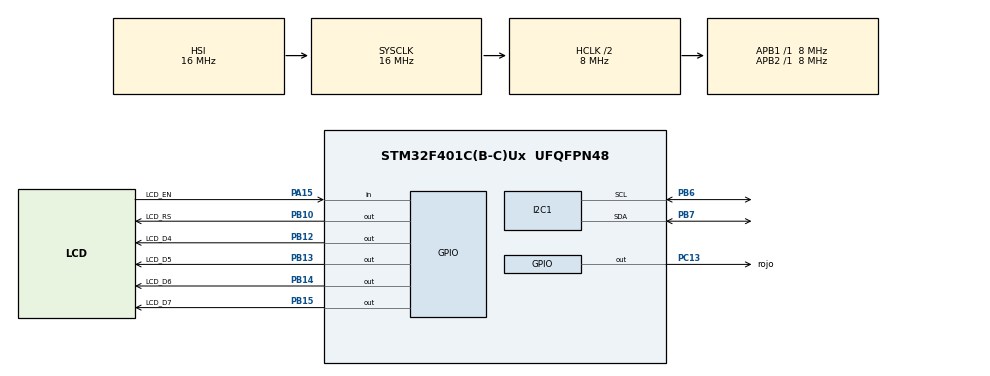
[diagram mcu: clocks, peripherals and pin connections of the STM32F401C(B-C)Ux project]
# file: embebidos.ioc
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Mcu.Family=STM32F4
Mcu.Name=STM32F401C(B-C)Ux
Mcu.Package=UFQFPN48
Mcu.UserConstants=i2c_pin,$$_I2C1_IP_HANDLE_$$
NVIC.PriorityGroup=NVIC_PRIORITYGROUP_4
PA15.GPIO_Label=LCD_EN
PA15.Signal=GPIO_Input
PB10.GPIO_Label=LCD_RS
PB10.Signal=GPIO_Output
PB12.GPIO_Label=LCD_D4
PB12.Signal=GPIO_Output
PB13.GPIO_Label=LCD_D5
PB13.Signal=GPIO_Output
PB14.GPIO_Label=LCD_D6
PB14.Signal=GPIO_Output
PB15.GPIO_Label=LCD_D7
PB15.Signal=GPIO_Output
PB6.Mode=I2C
PB6.Signal=I2C1_SCL
PB7.Mode=I2C
PB7.Signal=I2C1_SDA
PC13-ANTI_TAMP.GPIO_Label=rojo
PC13-ANTI_TAMP.Signal=GPIO_Output
ProjectManager.HeapSize=0x200
ProjectManager.StackSize=0x400
ProjectManager.TargetToolchain=CMake
RCC.AHBCLKDivider=RCC_SYSCLK_DIV2
RCC.AHBFreq_Value=8000000
RCC.APB1Freq_Value=8000000
RCC.APB1TimFreq_Value=8000000
RCC.APB2Freq_Value=8000000
RCC.APB2TimFreq_Value=8000000
RCC.CortexFreq_Value=8000000
RCC.HCLKFreq_Value=8000000
RCC.HSE_VALUE=25000000
RCC.HSI_VALUE=16000000
RCC.LSE_VALUE=32768
RCC.SYSCLKFreq_VALUE=16000000
RCC.VCOOutputFreq_Value=192000000
board=custom

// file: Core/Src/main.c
/* USER CODE BEGIN Header */
/**
  ******************************************************************************
  * @file           : main.c
  * @brief          : Main program body
  ******************************************************************************
  * @attention
  *
  * Copyright (c) 2026 STMicroelectronics.
  * All rights reserved.
  *
  * This software is licensed under terms that can be found in the LICENSE file
  * in the root directory of this software component.
  * If no LICENSE file comes with this software, it is provided AS-IS.
  *
  ******************************************************************************
  */
/* USER CODE END Header */
#include "main.h"

/* USER CODE BEGIN Includes */
#include "LCD_I2C.H"
#include "lcd.h"

const char rayo[8] = {0x02, 0x04, 0x08, 0x1F, 0x04, 0x08, 0x10, 0x00};
const char carita[8] = {0x00, 0x0A, 0x0A, 0x00, 0x11, 0x0E, 0x00, 0x00};

/* USER CODE END Includes */

I2C_HandleTypeDef hi2c1;

void SystemClock_Config(void);
static void MX_GPIO_Init(void);
static void MX_I2C1_Init(void);

int main(void)
{

  /* MCU Configuration--------------------------------------------------------*/

  /* Reset of all peripherals, Initializes the Flash interface and the Systick. */
  HAL_Init();

  /* Configure the system clock */
  SystemClock_Config();

  /* Initialize all configured peripherals */
  MX_GPIO_Init();
  MX_I2C1_Init();
  /* USER CODE BEGIN 2 */

  I2C_Lcd_Init();
  I2C_Lcd_Cmd(_LCD_CLEAR);
  I2C_Lcd_Cmd(_LCD_CURSOR_OFF);
  I2C_Lcd_Text(1, 1, "Carolina");
  I2C_Lcd_Text(2, 1, "Velasco");
  I2C_Lcd_Chr(4, 15, 'C');
  I2C_Lcd_chr_propio(2, 15, 3, rayo);
  I2C_Lcd_chr_propio(1, 15, 2, carita);

  /* USER CODE END 2 */

  /* Infinite loop */
  while (1)
  {

  }
}

void SystemClock_Config(void)
{
  RCC_OscInitTypeDef RCC_OscInitStruct = {0};
  RCC_ClkInitTypeDef RCC_ClkInitStruct = {0};

  /** Configure the main internal regulator output voltage
  */
  __HAL_RCC_PWR_CLK_ENABLE();
  __HAL_PWR_VOLTAGESCALING_CONFIG(PWR_REGULATOR_VOLTAGE_SCALE2);

  /** Initializes the RCC Oscillators according to the specified parameters
  * in the RCC_OscInitTypeDef structure.
  */
  RCC_OscInitStruct.OscillatorType = RCC_OSCILLATORTYPE_HSI;
  RCC_OscInitStruct.HSIState = RCC_HSI_ON;
  RCC_OscInitStruct.HSICalibrationValue = RCC_HSICALIBRATION_DEFAULT;
  RCC_OscInitStruct.PLL.PLLState = RCC_PLL_NONE;
  if (HAL_RCC_OscConfig(&RCC_OscInitStruct) != HAL_OK)
  {
    Error_Handler();
  }

  /** Initializes the CPU, AHB and APB buses clocks
  */
  RCC_ClkInitStruct.ClockType = RCC_CLOCKTYPE_HCLK|RCC_CLOCKTYPE_SYSCLK
                              |RCC_CLOCKTYPE_PCLK1|RCC_CLOCKTYPE_PCLK2;
  RCC_ClkInitStruct.SYSCLKSource = RCC_SYSCLKSOURCE_HSI;
  RCC_ClkInitStruct.AHBCLKDivider = RCC_SYSCLK_DIV2;
  RCC_ClkInitStruct.APB1CLKDivider = RCC_HCLK_DIV1;
  RCC_ClkInitStruct.APB2CLKDivider = RCC_HCLK_DIV1;

  if (HAL_RCC_ClockConfig(&RCC_ClkInitStruct, FLASH_LATENCY_0) != HAL_OK)
  {
    Error_Handler();
  }
}

static void MX_I2C1_Init(void)
{

  hi2c1.Instance = I2C1;
  hi2c1.Init.ClockSpeed = 100000;
  hi2c1.Init.DutyCycle = I2C_DUTYCYCLE_2;
  hi2c1.Init.OwnAddress1 = 0;
  hi2c1.Init.AddressingMode = I2C_ADDRESSINGMODE_7BIT;
  hi2c1.Init.DualAddressMode = I2C_DUALADDRESS_DISABLE;
  hi2c1.Init.OwnAddress2 = 0;
  hi2c1.Init.GeneralCallMode = I2C_GENERALCALL_DISABLE;
  hi2c1.Init.NoStretchMode = I2C_NOSTRETCH_DISABLE;
  if (HAL_I2C_Init(&hi2c1) != HAL_OK)
  {
    Error_Handler();
  }

}

static void MX_GPIO_Init(void)
{
  GPIO_InitTypeDef GPIO_InitStruct = {0};

  /* GPIO Ports Clock Enable */
  __HAL_RCC_GPIOC_CLK_ENABLE();
  __HAL_RCC_GPIOB_CLK_ENABLE();
  __HAL_RCC_GPIOA_CLK_ENABLE();

  /*Configure GPIO pin Output Level */
  HAL_GPIO_WritePin(rojo_GPIO_Port, rojo_Pin, GPIO_PIN_RESET);

  /*Configure GPIO pin Output Level */
  HAL_GPIO_WritePin(GPIOB, LCD_RS_Pin|LCD_D4_Pin|LCD_D5_Pin|LCD_D6_Pin
                          |LCD_D7_Pin, GPIO_PIN_RESET);

  /*Configure GPIO pin : rojo_Pin */
  GPIO_InitStruct.Pin = rojo_Pin;
  GPIO_InitStruct.Mode = GPIO_MODE_OUTPUT_PP;
  GPIO_InitStruct.Pull = GPIO_NOPULL;
  GPIO_InitStruct.Speed = GPIO_SPEED_FREQ_LOW;
  HAL_GPIO_Init(rojo_GPIO_Port, &GPIO_InitStruct);

  /*Configure GPIO pins : LCD_RS_Pin LCD_D4_Pin LCD_D5_Pin LCD_D6_Pin
                           LCD_D7_Pin */
  GPIO_InitStruct.Pin = LCD_RS_Pin|LCD_D4_Pin|LCD_D5_Pin|LCD_D6_Pin
                          |LCD_D7_Pin;
  GPIO_InitStruct.Mode = GPIO_MODE_OUTPUT_PP;
  GPIO_InitStruct.Pull = GPIO_NOPULL;
  GPIO_InitStruct.Speed = GPIO_SPEED_FREQ_LOW;
  HAL_GPIO_Init(GPIOB, &GPIO_InitStruct);

  /*Configure GPIO pin : LCD_EN_Pin */
  GPIO_InitStruct.Pin = LCD_EN_Pin;
  GPIO_InitStruct.Mode = GPIO_MODE_INPUT;
  GPIO_InitStruct.Pull = GPIO_NOPULL;
  HAL_GPIO_Init(LCD_EN_GPIO_Port, &GPIO_InitStruct);

}

void Error_Handler(void)
{
  __disable_irq();
  while (1)
  {
  }
}
